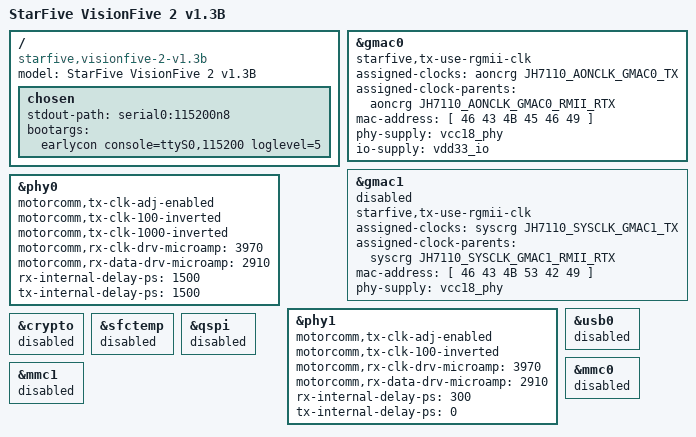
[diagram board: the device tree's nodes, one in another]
// SPDX-License-Identifier: GPL-2.0 OR MIT
/*
 * Copyright (C) 2022 StarFive Technology Co., Ltd.
 * Copyright (C) 2022 Emil Renner Berthing <kernel@esmil.dk>
 */

/dts-v1/;
#include "jh7110-starfive-visionfive-2.dtsi"

/ {
	model = "StarFive VisionFive 2 v1.3B";
	compatible = "starfive,visionfive-2-v1.3b", "starfive,jh7110";

	chosen {
		stdout-path = "serial0:115200n8";
		bootargs = "earlycon console=ttyS0,115200 loglevel=5";
	};
};

&gmac0 {
	// status = "disabled";
	starfive,tx-use-rgmii-clk;
	assigned-clocks = <&aoncrg JH7110_AONCLK_GMAC0_TX>;
	assigned-clock-parents = <&aoncrg JH7110_AONCLK_GMAC0_RMII_RTX>;
	mac-address = [ 46 43 4B 45 46 49 ];
	// Power to the People, Hell Yea (um PHY)!
	phy-supply = <&vcc18_phy>;
	io-supply = <&vdd33_io>;
};

&gmac1 {
	status = "disabled";
	starfive,tx-use-rgmii-clk;
	assigned-clocks = <&syscrg JH7110_SYSCLK_GMAC1_TX>;
	assigned-clock-parents = <&syscrg JH7110_SYSCLK_GMAC1_RMII_RTX>;
	mac-address = [ 46 43 4B 53 42 49 ];
	phy-supply = <&vcc18_phy>;
};

&phy0 {
	motorcomm,tx-clk-adj-enabled;
	motorcomm,tx-clk-100-inverted;
	motorcomm,tx-clk-1000-inverted;
	motorcomm,rx-clk-drv-microamp = <3970>;
	motorcomm,rx-data-drv-microamp = <2910>;
	rx-internal-delay-ps = <1500>;
	tx-internal-delay-ps = <1500>;
};

&phy1 {
	motorcomm,tx-clk-adj-enabled;
	motorcomm,tx-clk-100-inverted;
	motorcomm,rx-clk-drv-microamp = <3970>;
	motorcomm,rx-data-drv-microamp = <2910>;
	rx-internal-delay-ps = <300>;
	tx-internal-delay-ps = <0>;
};

// save power
&usb0 {
	status = "disabled";
};

// oopses
&crypto {
	status = "disabled";
};

// hangs
&sfctemp {
	status = "disabled";
};

// hangs
&qspi {
	status = "disabled";
};

&mmc0 {
	status = "disabled";
};

&mmc1 {
	status = "disabled";
};
